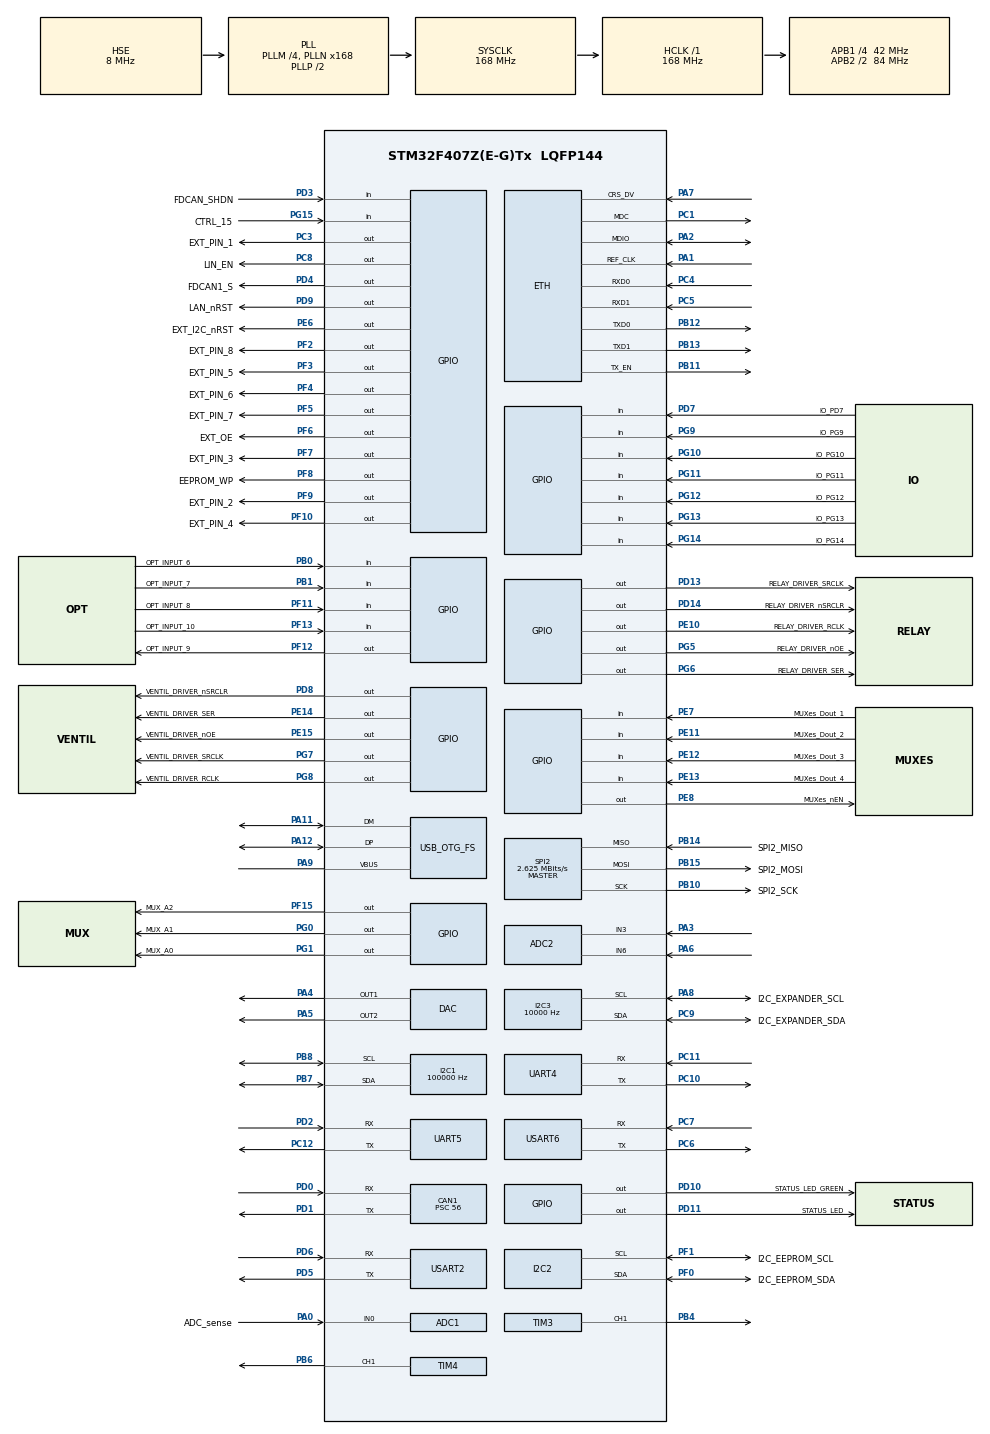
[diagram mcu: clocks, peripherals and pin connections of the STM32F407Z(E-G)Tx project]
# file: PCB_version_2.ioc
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ADC1.Channel-1\#ChannelRegularConversion=ADC_CHANNEL_TEMPSENSOR
ADC1.ContinuousConvMode=ENABLE
ADC1.EOCSelection=ADC_EOC_SEQ_CONV
ADC1.NbrOfConversion=1
ADC1.NbrOfConversionFlag=1
ADC1.SamplingTime-1\#ChannelRegularConversion=ADC_SAMPLETIME_480CYCLES
ADC1.master=1
ADC2.Channel-3\#ChannelRegularConversion=ADC_CHANNEL_3
ADC2.ContinuousConvMode=DISABLE
ADC2.InjNumberOfConversion=0
ADC2.NbrOfConversion=1
ADC2.NbrOfConversionFlag=1
ADC2.Rank-3\#ChannelRegularConversion=1
ADC2.SamplingTime-3\#ChannelRegularConversion=ADC_SAMPLETIME_480CYCLES
ADC2.ScanConvMode=DISABLE
CAN1.CalculateBaudRate=249999
CAN1.CalculateTimeBit=4000
CAN1.CalculateTimeQuantum=1333.3333333333335
CAN1.Mode=CAN_MODE_LOOPBACK
CAN1.Prescaler=56
Dma.Request0=UART4_RX
Dma.Request1=UART5_RX
Dma.UART4_RX.0.Direction=DMA_PERIPH_TO_MEMORY
Dma.UART4_RX.0.FIFOMode=DMA_FIFOMODE_DISABLE
Dma.UART4_RX.0.Instance=DMA1_Stream2
Dma.UART4_RX.0.MemDataAlignment=DMA_MDATAALIGN_BYTE
Dma.UART4_RX.0.MemInc=DMA_MINC_ENABLE
Dma.UART4_RX.0.Mode=DMA_CIRCULAR
Dma.UART4_RX.0.PeriphDataAlignment=DMA_PDATAALIGN_BYTE
Dma.UART4_RX.0.PeriphInc=DMA_PINC_DISABLE
Dma.UART4_RX.0.Priority=DMA_PRIORITY_MEDIUM
Dma.UART5_RX.1.Direction=DMA_PERIPH_TO_MEMORY
Dma.UART5_RX.1.FIFOMode=DMA_FIFOMODE_DISABLE
Dma.UART5_RX.1.Instance=DMA1_Stream0
Dma.UART5_RX.1.MemDataAlignment=DMA_MDATAALIGN_BYTE
Dma.UART5_RX.1.MemInc=DMA_MINC_ENABLE
Dma.UART5_RX.1.Mode=DMA_CIRCULAR
Dma.UART5_RX.1.PeriphDataAlignment=DMA_PDATAALIGN_BYTE
Dma.UART5_RX.1.PeriphInc=DMA_PINC_DISABLE
Dma.UART5_RX.1.Priority=DMA_PRIORITY_MEDIUM
ETH.MACAddr=00\:80\:E1\:01\:23\:45
ETH.MediaInterface=HAL_ETH_RMII_MODE
FREERTOS.BinarySemaphores01=InitDoneSemaphore,Static,InitDoneSemaphoreControlBlock,Available
FREERTOS.INCLUDE_eTaskGetState=1
FREERTOS.INCLUDE_pcTaskGetTaskName=1
FREERTOS.INCLUDE_uxTaskGetStackHighWaterMark=1
FREERTOS.INCLUDE_uxTaskGetStackHighWaterMark2=1
FREERTOS.INCLUDE_vTaskCleanUpResources=1
FREERTOS.INCLUDE_vTaskDelayUntil=1
FREERTOS.INCLUDE_xQueueGetMutexHolder=1
FREERTOS.INCLUDE_xSemaphoreGetMutexHolder=1
FREERTOS.INCLUDE_xTaskAbortDelay=1
FREERTOS.INCLUDE_xTaskGetCurrentTaskHandle=1
FREERTOS.INCLUDE_xTaskGetHandle=1
FREERTOS.MEMORY_ALLOCATION=2
FREERTOS.Tasks01=defaultTask,0,256,StartDefaultTask,Default,NULL,Static,defaultTaskBuffer,defaultTaskControlBlock;blinkTask,-1,128,blinkTaskEntry,Default,NULL,Static,blinkTaskBuffer,blinkTaskControlBlock;watchdogTask,-1,128,watchDogReset,Default,NULL,Static,watchdogTaskBuffer,watchdogTaskControlBlock;TcpServerTask,0,256,TcpServerTaskStart,Default,NULL,Static,TcpServerTaskBuffer,TcpServerTaskControlBlock;UsbTask,0,256,UsbTaskStart,Default,NULL,Static,UsbTaskBuffer,UsbTaskControlBlock;RS232Task,0,256,RS232TaskStart,Default,NULL,Static,RS232TaskBuffer,RS232TaskControlBlock;CommParserTask,0,2048,CommParserTaskStart,Default,NULL,Static,CommParserTaskBuffer,CommParserTaskControlBlock
FREERTOS.configENABLE_FPU=1
FREERTOS.configMINIMAL_STACK_SIZE=128
FREERTOS.configTOTAL_HEAP_SIZE=10000
FREERTOS.configUSE_NEWLIB_REENTRANT=1
I2C1.ClockSpeed=100000
I2C1.I2C_Mode=I2C_Fast
I2C3.ClockSpeed=10000
I2C3.I2C_Mode=I2C_Fast
I2C3.NoStretchMode=I2C_NOSTRETCH_DISABLE
IWDG.Prescaler=IWDG_PRESCALER_128
IWDG.Reload=2500
LWIP.BSP.number=1
LWIP.CMSIS_VERSION-Enabled=1
LWIP.GATEWAY_ADDRESS=192.168.000.001
LWIP.IP_ADDRESS=192.168.000.035
LWIP.LWIP_DHCP=0
LWIP.NETMASK_ADDRESS=255.255.255.000
LWIP.Version=v2.1.2_Cube
LWIP0.BSP.STBoard=false
LWIP0.BSP.api=BSP_COMPONENT_DRIVER
LWIP0.BSP.component=DP83848
LWIP0.BSP.instance=DP83848
LWIP0.BSP.name=Driver_PHY
LWIP0.BSP.semaphore=S_DP83848
LWIP0.BSP.solution=DP83848
Mcu.Family=STM32F4
Mcu.Name=STM32F407Z(E-G)Tx
Mcu.Package=LQFP144
NVIC.CAN1_RX0_IRQn=true\:5\:0\:false\:false\:true\:true\:true\:true\:true
NVIC.CAN1_RX1_IRQn=true\:5\:0\:false\:false\:true\:true\:true\:true\:true
NVIC.DMA1_Stream0_IRQn=true\:5\:0\:false\:false\:true\:true\:false\:true\:true
NVIC.DMA1_Stream2_IRQn=true\:5\:0\:false\:false\:true\:true\:false\:true\:true
NVIC.ETH_IRQn=true\:5\:0\:false\:false\:true\:true\:true\:true\:true
NVIC.OTG_FS_IRQn=true\:5\:0\:false\:false\:true\:true\:false\:true\:true
NVIC.PriorityGroup=NVIC_PRIORITYGROUP_4
NVIC.TIM1_TRG_COM_TIM11_IRQn=true\:5\:0\:false\:false\:true\:true\:true\:true\:true
NVIC.TIM7_IRQn=true\:5\:0\:false\:false\:true\:true\:true\:true\:true
NVIC.TIM8_TRG_COM_TIM14_IRQn=true\:15\:0\:false\:false\:true\:false\:false\:true\:true
NVIC.TimeBase=TIM8_TRG_COM_TIM14_IRQn
NVIC.TimeBaseIP=TIM14
NVIC.UART4_IRQn=true\:5\:0\:false\:false\:true\:true\:true\:true\:true
NVIC.UART5_IRQn=true\:5\:0\:false\:false\:true\:true\:true\:true\:true
PA0-WKUP.GPIO_Label=ADC_sense
PA0-WKUP.Signal=ADCx_IN0
PA1.Mode=RMII
PA1.Signal=ETH_REF_CLK
PA11.Mode=Device_Only
PA11.Signal=USB_OTG_FS_DM
PA12.Mode=Device_Only
PA12.Signal=USB_OTG_FS_DP
PA13.Mode=Trace_Asynchronous_SW
PA13.Signal=SYS_JTMS-SWDIO
PA14.Mode=Trace_Asynchronous_SW
PA14.Signal=SYS_JTCK-SWCLK
PA2.Mode=RMII
PA2.Signal=ETH_MDIO
PA3.Signal=ADCx_IN3
PA4.Signal=COMP_DAC1_group
PA5.Signal=COMP_DAC2_group
PA6.Signal=ADCx_IN6
PA7.Mode=RMII
PA7.Signal=ETH_CRS_DV
PA8.GPIO_Label=I2C_EXPANDER_SCL
PA8.Mode=I2C
PA8.Signal=I2C3_SCL
PA9.Mode=Activate_VBUS
PA9.Signal=USB_OTG_FS_VBUS
PB0.GPIO_Label=OPT_INPUT_6
PB0.Signal=GPIO_Input
PB1.GPIO_Label=OPT_INPUT_7
PB1.Signal=GPIO_Input
PB10.GPIO_Label=SPI2_SCK
PB10.GPIO_PuPd=GPIO_NOPULL
PB10.Mode=Full_Duplex_Master
PB10.Signal=SPI2_SCK
PB11.Mode=RMII
PB11.Signal=ETH_TX_EN
PB12.Mode=RMII
PB12.Signal=ETH_TXD0
PB13.Mode=RMII
PB13.Signal=ETH_TXD1
PB14.GPIO_Label=SPI2_MISO
PB14.Mode=Full_Duplex_Master
PB14.Signal=SPI2_MISO
PB15.GPIO_Label=SPI2_MOSI
PB15.Mode=Full_Duplex_Master
PB15.Signal=SPI2_MOSI
PB3.Mode=Trace_Asynchronous_SW
PB3.Signal=SYS_JTDO-SWO
PB4.Signal=S_TIM3_CH1
PB6.Signal=S_TIM4_CH1
PB7.Mode=I2C
PB7.Signal=I2C1_SDA
PB8.Mode=I2C
PB8.Signal=I2C1_SCL
PC1.Mode=RMII
PC1.Signal=ETH_MDC
PC10.Mode=Asynchronous
PC10.Signal=UART4_TX
PC11.Mode=Asynchronous
PC11.Signal=UART4_RX
PC12.Mode=Asynchronous
PC12.Signal=UART5_TX
PC3.GPIO_Label=EXT_PIN_1
PC3.Signal=GPIO_Output
PC4.Mode=RMII
PC4.Signal=ETH_RXD0
PC5.Mode=RMII
PC5.Signal=ETH_RXD1
PC6.Mode=LIN
PC6.Signal=USART6_TX
PC7.Mode=LIN
PC7.Signal=USART6_RX
PC8.GPIO_Label=LIN_EN
PC8.Signal=GPIO_Output
PC9.GPIO_Label=I2C_EXPANDER_SDA
PC9.Mode=I2C
PC9.Signal=I2C3_SDA
PD0.GPIO_PuPd=GPIO_NOPULL
PD0.Mode=CAN_Activate
PD0.Signal=CAN1_RX
PD1.GPIO_PuPd=GPIO_NOPULL
PD1.Mode=CAN_Activate
PD1.Signal=CAN1_TX
PD10.GPIO_Label=STATUS_LED_GREEN
PD10.Signal=GPIO_Output
PD11.GPIO_Label=STATUS_LED
PD11.Signal=GPIO_Output
PD13.GPIO_Label=RELAY_DRIVER_SRCLK
PD13.Signal=GPIO_Output
PD14.GPIO_Label=RELAY_DRIVER_nSRCLR
PD14.Signal=GPIO_Output
PD2.Mode=Asynchronous
PD2.Signal=UART5_RX
PD3.GPIO_Label=FDCAN_SHDN
PD3.Signal=GPIO_Input
PD4.GPIO_Label=FDCAN1_S
PD4.Signal=GPIO_Output
PD5.Mode=Asynchronous
PD5.Signal=USART2_TX
PD6.Mode=Asynchronous
PD6.Signal=USART2_RX
PD7.GPIO_Label=IO_PD7
PD7.Signal=GPIO_Input
PD8.GPIO_Label=VENTIL_DRIVER_nSRCLR
PD8.Signal=GPIO_Output
PD9.GPIO_Label=LAN_nRST
PD9.Signal=GPIO_Output
PE10.GPIO_Label=RELAY_DRIVER_RCLK
PE10.Signal=GPIO_Output
PE11.GPIO_Label=MUXes_Dout_2
PE11.Signal=GPIO_Input
PE12.GPIO_Label=MUXes_Dout_3
PE12.Signal=GPIO_Input
PE13.GPIO_Label=MUXes_Dout_4
PE13.Signal=GPIO_Input
PE14.GPIO_Label=VENTIL_DRIVER_SER
PE14.Signal=GPIO_Output
PE15.GPIO_Label=VENTIL_DRIVER_nOE
PE15.Signal=GPIO_Output
PE6.GPIO_Label=EXT_I2C_nRST
PE6.Signal=GPIO_Output
PE7.GPIO_Label=MUXes_Dout_1
PE7.Signal=GPIO_Input
PE8.GPIO_Label=MUXes_nEN
PE8.GPIO_Speed=GPIO_SPEED_FREQ_MEDIUM
PE8.Signal=GPIO_Output
PF0.GPIO_Label=I2C_EEPROM_SDA
PF0.GPIO_Pu=GPIO_PULLUP
PF0.Mode=I2C
PF0.Signal=I2C2_SDA
PF1.GPIO_Label=I2C_EEPROM_SCL
PF1.GPIO_Pu=GPIO_PULLUP
PF1.Mode=I2C
PF1.Signal=I2C2_SCL
PF10.GPIO_Label=EXT_PIN_4
PF10.Signal=GPIO_Output
PF11.GPIO_Label=OPT_INPUT_8
PF11.Signal=GPIO_Input
PF12.GPIO_Label=OPT_INPUT_9
PF12.Signal=GPIO_Output
PF13.GPIO_Label=OPT_INPUT_10
PF13.Signal=GPIO_Input
PF15.GPIO_Label=MUX_A2
PF15.Signal=GPIO_Output
PF2.GPIO_Label=EXT_PIN_8
PF2.Signal=GPIO_Output
PF3.GPIO_Label=EXT_PIN_5
PF3.Signal=GPIO_Output
PF4.GPIO_Label=EXT_PIN_6
PF4.Signal=GPIO_Output
PF5.GPIO_Label=EXT_PIN_7
PF5.Signal=GPIO_Output
PF6.GPIO_Label=EXT_OE
PF6.Signal=GPIO_Output
PF7.GPIO_Label=EXT_PIN_3
PF7.Signal=GPIO_Output
PF8.GPIO_Label=EEPROM_WP
PF8.Signal=GPIO_Output
PF9.GPIO_Label=EXT_PIN_2
PF9.Signal=GPIO_Output
PG0.GPIO_Label=MUX_A1
PG0.Signal=GPIO_Output
PG1.GPIO_Label=MUX_A0
PG1.GPIO_Speed=GPIO_SPEED_FREQ_MEDIUM
PG1.Signal=GPIO_Output
PG10.GPIO_Label=IO_PG10
PG10.Signal=GPIO_Input
PG11.GPIO_Label=IO_PG11
PG11.Signal=GPIO_Input
PG12.GPIO_Label=IO_PG12
PG12.Signal=GPIO_Input
PG13.GPIO_Label=IO_PG13
PG13.Signal=GPIO_Input
PG14.GPIO_Label=IO_PG14
PG14.Signal=GPIO_Input
PG15.GPIO_Label=CTRL_15
PG15.Signal=GPIO_Input
PG5.GPIO_Label=RELAY_DRIVER_nOE
PG5.Signal=GPIO_Output
PG6.GPIO_Label=RELAY_DRIVER_SER
PG6.Signal=GPIO_Output
PG7.GPIO_Label=VENTIL_DRIVER_SRCLK
PG7.Signal=GPIO_Output
PG8.GPIO_Label=VENTIL_DRIVER_RCLK
PG8.Signal=GPIO_Output
PG9.GPIO_Label=IO_PG9
PG9.Signal=GPIO_Input
PH0-OSC_IN.Mode=HSE-External-Oscillator
PH0-OSC_IN.Signal=RCC_OSC_IN
PH1-OSC_OUT.Mode=HSE-External-Oscillator
PH1-OSC_OUT.Signal=RCC_OSC_OUT
ProjectManager.HeapSize=0x200
ProjectManager.StackSize=0x400
ProjectManager.TargetToolchain=CMake
RCC.48MHZClocksFreq_Value=48000000
RCC.AHBFreq_Value=168000000
RCC.APB1CLKDivider=RCC_HCLK_DIV4
RCC.APB1Freq_Value=42000000
RCC.APB1TimFreq_Value=84000000
RCC.APB2CLKDivider=RCC_HCLK_DIV2
RCC.APB2Freq_Value=84000000
RCC.APB2TimFreq_Value=168000000
RCC.CortexFreq_Value=168000000
RCC.HCLKFreq_Value=168000000
RCC.HSE_VALUE=8000000
RCC.HSI_VALUE=16000000
RCC.LSE_VALUE=32768
RCC.PLLM=4
RCC.PLLN=168
RCC.PLLQ=7
RCC.RCC_RTC_Clock_Source=RCC_RTCCLKSOURCE_LSE
RCC.RCC_RTC_Clock_SourceVirtual=RCC_RTCCLKSOURCE_LSE
RCC.RCC_RTC_Clock_Source_FROM_HSE=RCC_RTCCLKSOURCE_HSE_DIV9
RCC.SYSCLKFreq_VALUE=168000000
RCC.SYSCLKSource=RCC_SYSCLKSOURCE_PLLCLK
RCC.VCOOutputFreq_Value=336000000
SH.ADCx_IN0.0=ADC1_IN0,IN0
SH.ADCx_IN3.0=ADC2_IN3,IN3
SH.ADCx_IN6.0=ADC2_IN6,IN6
SH.COMP_DAC1_group.0=DAC_OUT1,DAC_OUT1
SH.COMP_DAC2_group.0=DAC_OUT2,DAC_OUT2
SH.S_TIM3_CH1.0=TIM3_CH1,PWM Generation1 CH1
SH.S_TIM4_CH1.0=TIM4_CH1,PWM Generation1 CH1
SPI2.BaudRatePrescaler=SPI_BAUDRATEPRESCALER_16
SPI2.CLKPhase=SPI_PHASE_2EDGE
SPI2.CLKPolarity=SPI_POLARITY_HIGH
SPI2.CalculateBaudRate=2.625 MBits/s
SPI2.Direction=SPI_DIRECTION_2LINES
SPI2.Mode=SPI_MODE_MASTER
SPI2.VirtualType=VM_MASTER
TIM11.AutoReloadPreload=TIM_AUTORELOAD_PRELOAD_ENABLE
TIM11.Period=420-1
TIM3.Channel-PWM\ Generation1\ CH1=TIM_CHANNEL_1
TIM4.Channel-PWM\ Generation1\ CH1=TIM_CHANNEL_1
TIM7.AutoReloadPreload=TIM_AUTORELOAD_PRELOAD_ENABLE
TIM7.Period=168-1
UART4.VirtualMode=Asynchronous
UART5.VirtualMode=Asynchronous
USART2.VirtualMode=VM_ASYNC
USART6.VirtualMode=VM_ASYNC
USB_DEVICE.CLASS_NAME_FS=CDC
USB_DEVICE.VirtualMode-CDC_FS=Cdc
USB_DEVICE.VirtualModeFS=Cdc_FS
USB_OTG_FS.VirtualMode=Device_Only
VP_ADC1_TempSens_Input.Mode=IN-TempSens
VP_ADC1_Vref_Input.Mode=IN-Vrefint
VP_FREERTOS_VS_CMSIS_V1.Mode=CMSIS_V1
VP_IWDG_VS_IWDG.Mode=IWDG_Activate
VP_LWIP_VS_Enabled.Mode=Enabled
VP_SYS_VS_tim14.Mode=TIM14
VP_TIM11_VS_ClockSourceINT.Mode=Enable_Timer
VP_TIM7_VS_ClockSourceINT.Mode=Enable_Timer
VP_USB_DEVICE_VS_USB_DEVICE_CDC_FS.Mode=CDC_FS
board=custom

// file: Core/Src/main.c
/* USER CODE BEGIN Header */
/**
  ******************************************************************************
  * @file           : main.c
  * @brief          : Main program body
  ******************************************************************************
  * @attention
  *
  * Copyright (c) 2023 STMicroelectronics.
  * All rights reserved.
  *
  * This software is licensed under terms that can be found in the LICENSE file
  * in the root directory of this software component.
  * If no LICENSE file comes with this software, it is provided AS-IS.
  *
  ******************************************************************************
  */
/* USER CODE END Header */
#include "main.h"
#include "cmsis_os.h"
#include "lwip.h"
#include "usb_device.h"

/* USER CODE BEGIN Includes */
#include "usbd_cdc_if.h"
#include "stdio.h"
#include "task.h"
#include "semphr.h"
#include "tcpserver.h"
#include "globals.h"
#include "USBMessageHanler.h"
#include "RELAYS_AND_IO_DRIVER.h"
#include "relayCards.h"
#include "I2C_PCA9548APWR_expander.h"
#include "RAFION_bitbang_I2C.h"

#include "VL53L1X_RAFIONTECH.h"
#include "commandParser.h"
#include "UartMessageHandler.h"
/* USER CODE END Includes */

/* USER CODE BEGIN PM */
HAL_StatusTypeDef status;
uint32_t Reg_Val;
extern RELAY_IO_DRIVER_STRUCT RELAY_IO_DRIVER;
extern ExternalPortMapping EXTERNAL_PORT_MAPPING;
extern ExternalRelayCard EXTERNAL_32_RELAY_CARD;

/* USER CODE END PM */

ADC_HandleTypeDef hadc1;
ADC_HandleTypeDef hadc2;

CAN_HandleTypeDef hcan1;

DAC_HandleTypeDef hdac;

I2C_HandleTypeDef hi2c1;
I2C_HandleTypeDef hi2c2;
I2C_HandleTypeDef hi2c3;

IWDG_HandleTypeDef hiwdg;

SPI_HandleTypeDef hspi2;

TIM_HandleTypeDef htim3;
TIM_HandleTypeDef htim4;
TIM_HandleTypeDef htim7;
TIM_HandleTypeDef htim11;

UART_HandleTypeDef huart4;
UART_HandleTypeDef huart5;
UART_HandleTypeDef huart2;
UART_HandleTypeDef huart6;
DMA_HandleTypeDef hdma_uart4_rx;
DMA_HandleTypeDef hdma_uart5_rx;

osThreadId defaultTaskHandle;
uint32_t defaultTaskBuffer[ 256 ];
osStaticThreadDef_t defaultTaskControlBlock;
osThreadId blinkTaskHandle;
uint32_t blinkTaskBuffer[ 128 ];
osStaticThreadDef_t blinkTaskControlBlock;
osThreadId watchdogTaskHandle;
uint32_t watchdogTaskBuffer[ 128 ];
osStaticThreadDef_t watchdogTaskControlBlock;
osThreadId TcpServerTaskHandle;
uint32_t TcpServerTaskBuffer[ 256 ];
osStaticThreadDef_t TcpServerTaskControlBlock;
osThreadId UsbTaskHandle;
uint32_t UsbTaskBuffer[ 256 ];
osStaticThreadDef_t UsbTaskControlBlock;
osThreadId RS232TaskHandle;
uint32_t RS232TaskBuffer[ 256 ];
osStaticThreadDef_t RS232TaskControlBlock;
osThreadId CommParserTaskHandle;
uint32_t CommParserTaskBuffer[ 2048 ];
osStaticThreadDef_t CommParserTaskControlBlock;
osSemaphoreId InitDoneSemaphoreHandle;
osStaticSemaphoreDef_t InitDoneSemaphoreControlBlock;
/* USER CODE BEGIN PV */
osMutexId take_measurement_mutex;
osMutexId isBusyWithSendingResponse_mutex;

uartHandlerStruct uart4_handler_struct = {
  .huart = &huart4,
  .message_was_received_flag = 0,
  .connected_as_bridge = 0,
  .uart_name = "RS232-1",
  .DMA_BUFFER_SIZE = CMD_UART_BUFFER_LENGTH
};

uartHandlerStruct uart5_handler_struct = {
  .huart = &huart5,
  .message_was_received_flag = 0,
  .connected_as_bridge = 0,
  .uart_name = "RS232-2",
  .DMA_BUFFER_SIZE = CMD_UART_BUFFER_LENGTH
};

PCA9548APWRHandle pca9548apwr_expander = {
    .nrst = EXT_I2C_nRST_Pin,
    .scl = I2C_EXPANDER_SCL_Pin,
    .sda = I2C_EXPANDER_SDA_Pin,
    .nrst_port = EXT_I2C_nRST_GPIO_Port,
    .scl_port = I2C_EXPANDER_SCL_GPIO_Port,
    .sda_port = I2C_EXPANDER_SDA_GPIO_Port,
    .i2c_handle = &hi2c3,
    .address = 0x70, //PCA9548APWR default address with all address pins grounded
    .selected_channel = PCA9548APWR_NO_CHANNEL_SELECTED,
    .clock_speed = 10000, //10kHz I2C speed
    .last_i2c_error = HAL_OK
};

  VL53L1X g_tof_sensor1;
  VL53L1X tof_sensor_instances[8];
  VL53L1X* tof_sensors[8]; //Array to hold up to 8 VL53L1X sensors
/* USER CODE END PV */

void SystemClock_Config(void);
static void MX_GPIO_Init(void);
static void MX_DMA_Init(void);
static void MX_ADC1_Init(void);
static void MX_ADC2_Init(void);
static void MX_DAC_Init(void);
static void MX_CAN1_Init(void);
static void MX_I2C1_Init(void);
static void MX_USART2_UART_Init(void);
static void MX_I2C2_Init(void);
static void MX_TIM11_Init(void);
static void MX_I2C3_Init(void);
static void MX_SPI2_Init(void);
static void MX_IWDG_Init(void);
static void MX_TIM3_Init(void);
static void MX_TIM4_Init(void);
static void MX_UART4_Init(void);
static void MX_UART5_Init(void);
static void MX_USART6_UART_Init(void);
static void MX_TIM7_Init(void);
void StartDefaultTask(void const * argument);
void blinkTaskEntry(void const * argument);
void watchDogReset(void const * argument);
void TcpServerTaskStart(void const * argument);
void UsbTaskStart(void const * argument);
void RS232TaskStart(void const * argument);
void CommParserTaskStart(void const * argument);

/* USER CODE BEGIN PFP */
//Redriect printf to USB CDC
int _write(int file, char *ptr, int len)
{
  CDC_Transmit_FS((uint8_t*)ptr, len);
  return len;
}

/* USER CODE END PFP */

/* USER CODE BEGIN 0 */
volatile const char *g_fault_reason = NULL;
volatile const char *g_fault_task_name = NULL;
volatile uint32_t g_fault_stack_r0 = 0;
volatile uint32_t g_fault_stack_r1 = 0;
volatile uint32_t g_fault_stack_r2 = 0;
volatile uint32_t g_fault_stack_r3 = 0;
volatile uint32_t g_fault_stack_r12 = 0;
volatile uint32_t g_fault_stack_lr = 0;
volatile uint32_t g_fault_stack_pc = 0;
volatile uint32_t g_fault_stack_psr = 0;
volatile uint32_t g_fault_sp = 0;
volatile uint32_t g_fault_exc_return = 0;
volatile uint32_t g_fault_cfsr = 0;
volatile uint32_t g_fault_hfsr = 0;
volatile uint32_t g_fault_dfsr = 0;
volatile uint32_t g_fault_afsr = 0;
volatile uint32_t g_fault_bfar = 0;
volatile uint32_t g_fault_mmfar = 0;

static void DebugTrap(const char *reason, const char *task_name)
{
  g_fault_reason = reason;
  g_fault_task_name = task_name;
  __disable_irq();
  __BKPT(0);
  while (1)
  {
  }
}

static uartHandlerStruct* GetRs232Handler(UART_HandleTypeDef *huart)
{
  // Implement the logic to get the UART handler based on the huart pointer
  // This is a placeholder implementation, replace with actual logic
  if (huart == &huart4)
  {
    return &uart4_handler_struct;
  }
  else if (huart == &huart5)
  {
    return &uart5_handler_struct;
  }
  return NULL;
}

void HAL_UARTEx_RxEventCallback(UART_HandleTypeDef *huart, uint16_t Size)
{
  uartHandlerStruct *uart_handler = GetRs232Handler(huart);
  uint16_t write_position = Size;
  uint16_t previous_position;
  uint16_t received_bytes;

  if (uart_handler == NULL)
  {
    return;
  }

  if (write_position > uart_handler->DMA_BUFFER_SIZE)
  {
    write_position = uart_handler->DMA_BUFFER_SIZE;
  }

  previous_position = uart_handler->dma_write_position;

  if (write_position == uart_handler->DMA_BUFFER_SIZE)
  {
    received_bytes = (uint16_t)(uart_handler->DMA_BUFFER_SIZE - previous_position);
    uart_handler->dma_write_position = 0U;
  }
  else if (write_position >= previous_position)
  {
    received_bytes = (uint16_t)(write_position - previous_position);
    uart_handler->dma_write_position = write_position;
  }
  else
  {
    received_bytes = (uint16_t)(uart_handler->DMA_BUFFER_SIZE - previous_position + write_position);
    uart_handler->dma_write_position = write_position;
  }

  if (received_bytes == 0U)
  {
    return;
  }

  if ((uint16_t)(uart_handler->dma_pending_bytes + received_bytes) > uart_handler->DMA_BUFFER_SIZE)
  {
    uart_handler->dma_pending_bytes = uart_handler->DMA_BUFFER_SIZE;
  }
  else
  {
    uart_handler->dma_pending_bytes = (uint16_t)(uart_handler->dma_pending_bytes + received_bytes);
  }

  uart_handler->message_length = uart_handler->dma_pending_bytes;
  uart_handler->message_was_received_flag = 1U;
}

/* USER CODE END 0 */

int main(void)
{

  /* MCU Configuration--------------------------------------------------------*/

  /* Reset of all peripherals, Initializes the Flash interface and the Systick. */
  HAL_Init();

  /* USER CODE BEGIN Init */
  //SCB->VTOR = 0x08020000; // Set vector table base address
  //eenable interrupts
  __enable_irq();

  SCB->SHCSR |= SCB_SHCSR_MEMFAULTENA_Msk |
                SCB_SHCSR_BUSFAULTENA_Msk |
                SCB_SHCSR_USGFAULTENA_Msk;
  SCB->CCR |= SCB_CCR_DIV_0_TRP_Msk;

  /* USER CODE END Init */

  /* Configure the system clock */
  SystemClock_Config();

  /* Initialize all configured peripherals */
  MX_GPIO_Init();
  MX_DMA_Init();
  MX_ADC1_Init();
  MX_ADC2_Init();
  MX_DAC_Init();
  MX_CAN1_Init();
  MX_I2C1_Init();
  MX_USART2_UART_Init();
  MX_I2C2_Init();
  MX_TIM11_Init();
  MX_I2C3_Init();
  MX_SPI2_Init();
  MX_IWDG_Init();
  MX_TIM3_Init();
  MX_TIM4_Init();
  MX_UART4_Init();
  MX_UART5_Init();
  MX_USART6_UART_Init();
  MX_TIM7_Init();
  /* USER CODE BEGIN 2 */
  HAL_GPIO_WritePin(STATUS_LED_GREEN_GPIO_Port,STATUS_LED_GREEN_Pin, GPIO_PIN_SET);
  HAL_ADC_Start(&hadc1);
  HAL_ADC_Start(&hadc2);
  HAL_TIM_Base_Start_IT(&htim11);
  HAL_TIM_Base_Start_IT(&htim7);

  RELAY_DRIVER_init(&RELAY_IO_DRIVER);
  HAL_GPIO_WritePin(EXTERNAL_PORT_MAPPING.EXT_OE_port, EXTERNAL_PORT_MAPPING.EXT_OE_pin, GPIO_PIN_SET);
  relayCardSetPort(0,&EXTERNAL_32_RELAY_CARD);
  HAL_GPIO_WritePin(LAN_nRST_GPIO_Port,LAN_nRST_Pin, GPIO_PIN_SET);
  HAL_Delay(100);

  /* USER CODE END 2 */

  /* USER CODE BEGIN RTOS_MUTEX */
  /* add mutexes, ... */
  commandTemplateMutex = xSemaphoreCreateMutex();
  if (commandTemplateMutex == NULL)
  {
    Error_Handler();
  }

  /* USER CODE END RTOS_MUTEX */

  /* Create the semaphores(s) */
  /* definition and creation of InitDoneSemaphore */
  osSemaphoreStaticDef(InitDoneSemaphore, &InitDoneSemaphoreControlBlock);
  InitDoneSemaphoreHandle = osSemaphoreCreate(osSemaphore(InitDoneSemaphore), 1);

  /* USER CODE BEGIN RTOS_SEMAPHORES */
  osMutexDef(take_measurement_mutex);
  take_measurement_mutex = osMutexCreate(osMutex(take_measurement_mutex));

  osMutexDef(isBusyWithSendingResponse_mutex);
  isBusyWithSendingResponse_mutex = osMutexCreate(osMutex(isBusyWithSendingResponse_mutex));
  /* add semaphores, ... */
  /* USER CODE END RTOS_SEMAPHORES */

  /* USER CODE BEGIN RTOS_QUEUES */
  /* add queues, ... */
  init_command_queue();
  if (commandQueueHandle == NULL)
  {
    Error_Handler();
  }
  /* USER CODE END RTOS_QUEUES */

  /* Create the thread(s) */
  /* definition and creation of defaultTask */
  osThreadStaticDef(defaultTask, StartDefaultTask, osPriorityNormal, 0, 256, defaultTaskBuffer, &defaultTaskControlBlock);
  defaultTaskHandle = osThreadCreate(osThread(defaultTask), NULL);

  /* definition and creation of blinkTask */
  osThreadStaticDef(blinkTask, blinkTaskEntry, osPriorityBelowNormal, 0, 128, blinkTaskBuffer, &blinkTaskControlBlock);
  blinkTaskHandle = osThreadCreate(osThread(blinkTask), NULL);

  /* definition and creation of watchdogTask */
  osThreadStaticDef(watchdogTask, watchDogReset, osPriorityBelowNormal, 0, 128, watchdogTaskBuffer, &watchdogTaskControlBlock);
  watchdogTaskHandle = osThreadCreate(osThread(watchdogTask), NULL);

  /* definition and creation of TcpServerTask */
  osThreadStaticDef(TcpServerTask, TcpServerTaskStart, osPriorityNormal, 0, 256, TcpServerTaskBuffer, &TcpServerTaskControlBlock);
  TcpServerTaskHandle = osThreadCreate(osThread(TcpServerTask), NULL);

  /* definition and creation of UsbTask */
  osThreadStaticDef(UsbTask, UsbTaskStart, osPriorityNormal, 0, 256, UsbTaskBuffer, &UsbTaskControlBlock);
  UsbTaskHandle = osThreadCreate(osThread(UsbTask), NULL);

  /* definition and creation of RS232Task */
  osThreadStaticDef(RS232Task, RS232TaskStart, osPriorityNormal, 0, 256, RS232TaskBuffer, &RS232TaskControlBlock);
  RS232TaskHandle = osThreadCreate(osThread(RS232Task), NULL);

  /* definition and creation of CommParserTask */
  osThreadStaticDef(CommParserTask, CommParserTaskStart, osPriorityNormal, 0, 2048, CommParserTaskBuffer, &CommParserTaskControlBlock);
  CommParserTaskHandle = osThreadCreate(osThread(CommParserTask), NULL);

  /* USER CODE BEGIN RTOS_THREADS */
  if ((defaultTaskHandle == NULL) ||
      (blinkTaskHandle == NULL) ||
      (watchdogTaskHandle == NULL) ||
      (TcpServerTaskHandle == NULL) ||
      (UsbTaskHandle == NULL) ||
      (RS232TaskHandle == NULL) ||
      (CommParserTaskHandle == NULL))
  {
    Error_Handler();
  }
  /* USER CODE END RTOS_THREADS */

  /* Start scheduler */
  osKernelStart();

  /* We should never get here as control is now taken by the scheduler */

  /* Infinite loop */
  while (1)
  {

  }
}

void SystemClock_Config(void)
{
  RCC_OscInitTypeDef RCC_OscInitStruct = {0};
  RCC_ClkInitTypeDef RCC_ClkInitStruct = {0};

  /** Configure the main internal regulator output voltage
  */
  __HAL_RCC_PWR_CLK_ENABLE();
  __HAL_PWR_VOLTAGESCALING_CONFIG(PWR_REGULATOR_VOLTAGE_SCALE1);

  /** Initializes the RCC Oscillators according to the specified parameters
  * in the RCC_OscInitTypeDef structure.
  */
  RCC_OscInitStruct.OscillatorType = RCC_OSCILLATORTYPE_LSI|RCC_OSCILLATORTYPE_HSE;
  RCC_OscInitStruct.HSEState = RCC_HSE_ON;
  RCC_OscInitStruct.LSIState = RCC_LSI_ON;
  RCC_OscInitStruct.PLL.PLLState = RCC_PLL_ON;
  RCC_OscInitStruct.PLL.PLLSource = RCC_PLLSOURCE_HSE;
  RCC_OscInitStruct.PLL.PLLM = 4;
  RCC_OscInitStruct.PLL.PLLN = 168;
  RCC_OscInitStruct.PLL.PLLP = RCC_PLLP_DIV2;
  RCC_OscInitStruct.PLL.PLLQ = 7;
  if (HAL_RCC_OscConfig(&RCC_OscInitStruct) != HAL_OK)
  {
    Error_Handler();
  }

  /** Initializes the CPU, AHB and APB buses clocks
  */
  RCC_ClkInitStruct.ClockType = RCC_CLOCKTYPE_HCLK|RCC_CLOCKTYPE_SYSCLK
                              |RCC_CLOCKTYPE_PCLK1|RCC_CLOCKTYPE_PCLK2;
  RCC_ClkInitStruct.SYSCLKSource = RCC_SYSCLKSOURCE_PLLCLK;
  RCC_ClkInitStruct.AHBCLKDivider = RCC_SYSCLK_DIV1;
  RCC_ClkInitStruct.APB1CLKDivider = RCC_HCLK_DIV4;
  RCC_ClkInitStruct.APB2CLKDivider = RCC_HCLK_DIV2;

  if (HAL_RCC_ClockConfig(&RCC_ClkInitStruct, FLASH_LATENCY_5) != HAL_OK)
  {
    Error_Handler();
  }
}

static void MX_ADC1_Init(void)
{

  ADC_ChannelConfTypeDef sConfig = {0};

  /** Configure the global features of the ADC (Clock, Resolution, Data Alignment and number of conversion)
  */
  hadc1.Instance = ADC1;
  hadc1.Init.ClockPrescaler = ADC_CLOCK_SYNC_PCLK_DIV4;
  hadc1.Init.Resolution = ADC_RESOLUTION_12B;
  hadc1.Init.ScanConvMode = DISABLE;
  hadc1.Init.ContinuousConvMode = ENABLE;
  hadc1.Init.DiscontinuousConvMode = DISABLE;
  hadc1.Init.ExternalTrigConvEdge = ADC_EXTERNALTRIGCONVEDGE_NONE;
  hadc1.Init.ExternalTrigConv = ADC_SOFTWARE_START;
  hadc1.Init.DataAlign = ADC_DATAALIGN_RIGHT;
  hadc1.Init.NbrOfConversion = 1;
  hadc1.Init.DMAContinuousRequests = DISABLE;
  hadc1.Init.EOCSelection = ADC_EOC_SEQ_CONV;
  if (HAL_ADC_Init(&hadc1) != HAL_OK)
  {
    Error_Handler();
  }

  /** Configure for the selected ADC regular channel its corresponding rank in the sequencer and its sample time.
  */
  sConfig.Channel = ADC_CHANNEL_TEMPSENSOR;
  sConfig.Rank = 1;
  sConfig.SamplingTime = ADC_SAMPLETIME_480CYCLES;
  if (HAL_ADC_ConfigChannel(&hadc1, &sConfig) != HAL_OK)
  {
    Error_Handler();
  }

}

static void MX_ADC2_Init(void)
{

  ADC_ChannelConfTypeDef sConfig = {0};

  /** Configure the global features of the ADC (Clock, Resolution, Data Alignment and number of conversion)
  */
  hadc2.Instance = ADC2;
  hadc2.Init.ClockPrescaler = ADC_CLOCK_SYNC_PCLK_DIV4;
  hadc2.Init.Resolution = ADC_RESOLUTION_12B;
  hadc2.Init.ScanConvMode = DISABLE;
  hadc2.Init.ContinuousConvMode = DISABLE;
  hadc2.Init.DiscontinuousConvMode = DISABLE;
  hadc2.Init.ExternalTrigConvEdge = ADC_EXTERNALTRIGCONVEDGE_NONE;
  hadc2.Init.ExternalTrigConv = ADC_SOFTWARE_START;
  hadc2.Init.DataAlign = ADC_DATAALIGN_RIGHT;
  hadc2.Init.NbrOfConversion = 1;
  hadc2.Init.DMAContinuousRequests = DISABLE;
  hadc2.Init.EOCSelection = ADC_EOC_SINGLE_CONV;
  if (HAL_ADC_Init(&hadc2) != HAL_OK)
  {
    Error_Handler();
  }

  /** Configure for the selected ADC regular channel its corresponding rank in the sequencer and its sample time.
  */
  sConfig.Channel = ADC_CHANNEL_3;
  sConfig.Rank = 1;
  sConfig.SamplingTime = ADC_SAMPLETIME_480CYCLES;
  if (HAL_ADC_ConfigChannel(&hadc2, &sConfig) != HAL_OK)
  {
    Error_Handler();
  }

}

static void MX_CAN1_Init(void)
{

  hcan1.Instance = CAN1;
  hcan1.Init.Prescaler = 56;
  hcan1.Init.Mode = CAN_MODE_LOOPBACK;
  hcan1.Init.SyncJumpWidth = CAN_SJW_1TQ;
  hcan1.Init.TimeSeg1 = CAN_BS1_1TQ;
  hcan1.Init.TimeSeg2 = CAN_BS2_1TQ;
  hcan1.Init.TimeTriggeredMode = DISABLE;
  hcan1.Init.AutoBusOff = DISABLE;
  hcan1.Init.AutoWakeUp = DISABLE;
  hcan1.Init.AutoRetransmission = DISABLE;
  hcan1.Init.ReceiveFifoLocked = DISABLE;
  hcan1.Init.TransmitFifoPriority = DISABLE;
  if (HAL_CAN_Init(&hcan1) != HAL_OK)
  {
    Error_Handler();
  }

}

static void MX_DAC_Init(void)
{

  DAC_ChannelConfTypeDef sConfig = {0};

  /** DAC Initialization
  */
  hdac.Instance = DAC;
  if (HAL_DAC_Init(&hdac) != HAL_OK)
  {
    Error_Handler();
  }

  /** DAC channel OUT1 config
  */
  sConfig.DAC_Trigger = DAC_TRIGGER_NONE;
  sConfig.DAC_OutputBuffer = DAC_OUTPUTBUFFER_ENABLE;
  if (HAL_DAC_ConfigChannel(&hdac, &sConfig, DAC_CHANNEL_1) != HAL_OK)
  {
    Error_Handler();
  }

  /** DAC channel OUT2 config
  */
  if (HAL_DAC_ConfigChannel(&hdac, &sConfig, DAC_CHANNEL_2) != HAL_OK)
  {
    Error_Handler();
  }
  /* USER CODE BEGIN DAC_Init 2 */
  HAL_DAC_Start(&hdac, DAC_CHANNEL_1);
  /* USER CODE END DAC_Init 2 */

}

static void MX_I2C1_Init(void)
{

  hi2c1.Instance = I2C1;
  hi2c1.Init.ClockSpeed = 100000;
  hi2c1.Init.DutyCycle = I2C_DUTYCYCLE_2;
  hi2c1.Init.OwnAddress1 = 0;
  hi2c1.Init.AddressingMode = I2C_ADDRESSINGMODE_7BIT;
  hi2c1.Init.DualAddressMode = I2C_DUALADDRESS_DISABLE;
  hi2c1.Init.OwnAddress2 = 0;
  hi2c1.Init.GeneralCallMode = I2C_GENERALCALL_DISABLE;
  hi2c1.Init.NoStretchMode = I2C_NOSTRETCH_DISABLE;
  if (HAL_I2C_Init(&hi2c1) != HAL_OK)
  {
    Error_Handler();
  }

}

static void MX_I2C2_Init(void)
{

  hi2c2.Instance = I2C2;
  hi2c2.Init.ClockSpeed = 100000;
  hi2c2.Init.DutyCycle = I2C_DUTYCYCLE_2;
  hi2c2.Init.OwnAddress1 = 0;
  hi2c2.Init.AddressingMode = I2C_ADDRESSINGMODE_7BIT;
  hi2c2.Init.DualAddressMode = I2C_DUALADDRESS_DISABLE;
  hi2c2.Init.OwnAddress2 = 0;
  hi2c2.Init.GeneralCallMode = I2C_GENERALCALL_DISABLE;
  hi2c2.Init.NoStretchMode = I2C_NOSTRETCH_DISABLE;
  if (HAL_I2C_Init(&hi2c2) != HAL_OK)
  {
    Error_Handler();
  }

}

static void MX_I2C3_Init(void)
{

  hi2c3.Instance = I2C3;
  hi2c3.Init.ClockSpeed = 10000;
  hi2c3.Init.DutyCycle = I2C_DUTYCYCLE_2;
  hi2c3.Init.OwnAddress1 = 0;
  hi2c3.Init.AddressingMode = I2C_ADDRESSINGMODE_7BIT;
  hi2c3.Init.DualAddressMode = I2C_DUALADDRESS_DISABLE;
  hi2c3.Init.OwnAddress2 = 0;
  hi2c3.Init.GeneralCallMode = I2C_GENERALCALL_DISABLE;
  hi2c3.Init.NoStretchMode = I2C_NOSTRETCH_DISABLE;
  if (HAL_I2C_Init(&hi2c3) != HAL_OK)
  {
    Error_Handler();
  }

}

static void MX_IWDG_Init(void)
{

  hiwdg.Instance = IWDG;
  hiwdg.Init.Prescaler = IWDG_PRESCALER_128;
  hiwdg.Init.Reload = 2500;
  if (HAL_IWDG_Init(&hiwdg) != HAL_OK)
  {
    Error_Handler();
  }

}

static void MX_SPI2_Init(void)
{

  /* SPI2 parameter configuration*/
  hspi2.Instance = SPI2;
  hspi2.Init.Mode = SPI_MODE_MASTER;
  hspi2.Init.Direction = SPI_DIRECTION_2LINES;
  hspi2.Init.DataSize = SPI_DATASIZE_8BIT;
  hspi2.Init.CLKPolarity = SPI_POLARITY_HIGH;
  hspi2.Init.CLKPhase = SPI_PHASE_2EDGE;
  hspi2.Init.NSS = SPI_NSS_SOFT;
  hspi2.Init.BaudRatePrescaler = SPI_BAUDRATEPRESCALER_16;
  hspi2.Init.FirstBit = SPI_FIRSTBIT_MSB;
  hspi2.Init.TIMode = SPI_TIMODE_DISABLE;
  hspi2.Init.CRCCalculation = SPI_CRCCALCULATION_DISABLE;
  hspi2.Init.CRCPolynomial = 10;
  if (HAL_SPI_Init(&hspi2) != HAL_OK)
  {
    Error_Handler();
  }

}

static void MX_TIM3_Init(void)
{

  TIM_MasterConfigTypeDef sMasterConfig = {0};
  TIM_OC_InitTypeDef sConfigOC = {0};

  htim3.Instance = TIM3;
  htim3.Init.Prescaler = 0;
  htim3.Init.CounterMode = TIM_COUNTERMODE_UP;
  htim3.Init.Period = 65535;
  htim3.Init.ClockDivision = TIM_CLOCKDIVISION_DIV1;
  htim3.Init.AutoReloadPreload = TIM_AUTORELOAD_PRELOAD_DISABLE;
  if (HAL_TIM_PWM_Init(&htim3) != HAL_OK)
  {
    Error_Handler();
  }
  sMasterConfig.MasterOutputTrigger = TIM_TRGO_RESET;
  sMasterConfig.MasterSlaveMode = TIM_MASTERSLAVEMODE_DISABLE;
  if (HAL_TIMEx_MasterConfigSynchronization(&htim3, &sMasterConfig) != HAL_OK)
  {
    Error_Handler();
  }
  sConfigOC.OCMode = TIM_OCMODE_PWM1;
  sConfigOC.Pulse = 0;
  sConfigOC.OCPolarity = TIM_OCPOLARITY_HIGH;
  sConfigOC.OCFastMode = TIM_OCFAST_DISABLE;
  if (HAL_TIM_PWM_ConfigChannel(&htim3, &sConfigOC, TIM_CHANNEL_1) != HAL_OK)
  {
    Error_Handler();
  }
  HAL_TIM_MspPostInit(&htim3);

}

static void MX_TIM4_Init(void)
{

  TIM_MasterConfigTypeDef sMasterConfig = {0};
  TIM_OC_InitTypeDef sConfigOC = {0};

  htim4.Instance = TIM4;
  htim4.Init.Prescaler = 0;
  htim4.Init.CounterMode = TIM_COUNTERMODE_UP;
  htim4.Init.Period = 65535;
  htim4.Init.ClockDivision = TIM_CLOCKDIVISION_DIV1;
  htim4.Init.AutoReloadPreload = TIM_AUTORELOAD_PRELOAD_DISABLE;
  if (HAL_TIM_PWM_Init(&htim4) != HAL_OK)
  {
    Error_Handler();
  }
  sMasterConfig.MasterOutputTrigger = TIM_TRGO_RESET;
  sMasterConfig.MasterSlaveMode = TIM_MASTERSLAVEMODE_DISABLE;
  if (HAL_TIMEx_MasterConfigSynchronization(&htim4, &sMasterConfig) != HAL_OK)
  {
    Error_Handler();
  }
  sConfigOC.OCMode = TIM_OCMODE_PWM1;
  sConfigOC.Pulse = 0;
  sConfigOC.OCPolarity = TIM_OCPOLARITY_HIGH;
  sConfigOC.OCFastMode = TIM_OCFAST_DISABLE;
  if (HAL_TIM_PWM_ConfigChannel(&htim4, &sConfigOC, TIM_CHANNEL_1) != HAL_OK)
  {
    Error_Handler();
  }
  HAL_TIM_MspPostInit(&htim4);

}

static void MX_TIM7_Init(void)
{

  TIM_MasterConfigTypeDef sMasterConfig = {0};

  htim7.Instance = TIM7;
  htim7.Init.Prescaler = 0;
  htim7.Init.CounterMode = TIM_COUNTERMODE_UP;
  htim7.Init.Period = 168-1;
  htim7.Init.AutoReloadPreload = TIM_AUTORELOAD_PRELOAD_ENABLE;
  if (HAL_TIM_Base_Init(&htim7) != HAL_OK)
  {
    Error_Handler();
  }
  sMasterConfig.MasterOutputTrigger = TIM_TRGO_RESET;
  sMasterConfig.MasterSlaveMode = TIM_MASTERSLAVEMODE_DISABLE;
  if (HAL_TIMEx_MasterConfigSynchronization(&htim7, &sMasterConfig) != HAL_OK)
  {
    Error_Handler();
  }

}

static void MX_TIM11_Init(void)
{

  htim11.Instance = TIM11;
  htim11.Init.Prescaler = 0;
  htim11.Init.CounterMode = TIM_COUNTERMODE_UP;
  htim11.Init.Period = 420-1;
  htim11.Init.ClockDivision = TIM_CLOCKDIVISION_DIV1;
  htim11.Init.AutoReloadPreload = TIM_AUTORELOAD_PRELOAD_ENABLE;
  if (HAL_TIM_Base_Init(&htim11) != HAL_OK)
  {
    Error_Handler();
  }

}

static void MX_UART4_Init(void)
{

  huart4.Instance = UART4;
  huart4.Init.BaudRate = 115200;
  huart4.Init.WordLength = UART_WORDLENGTH_8B;
  huart4.Init.StopBits = UART_STOPBITS_1;
  huart4.Init.Parity = UART_PARITY_NONE;
  huart4.Init.Mode = UART_MODE_TX_RX;
  huart4.Init.HwFlowCtl = UART_HWCONTROL_NONE;
  huart4.Init.OverSampling = UART_OVERSAMPLING_16;
  if (HAL_UART_Init(&huart4) != HAL_OK)
  {
    Error_Handler();
  }

}

static void MX_UART5_Init(void)
{

  huart5.Instance = UART5;
  huart5.Init.BaudRate = 115200;
  huart5.Init.WordLength = UART_WORDLENGTH_8B;
  huart5.Init.StopBits = UART_STOPBITS_1;
  huart5.Init.Parity = UART_PARITY_NONE;
  huart5.Init.Mode = UART_MODE_TX_RX;
  huart5.Init.HwFlowCtl = UART_HWCONTROL_NONE;
  huart5.Init.OverSampling = UART_OVERSAMPLING_16;
  if (HAL_UART_Init(&huart5) != HAL_OK)
  {
    Error_Handler();
  }

}

static void MX_USART2_UART_Init(void)
{

  huart2.Instance = USART2;
  huart2.Init.BaudRate = 115200;
  huart2.Init.WordLength = UART_WORDLENGTH_8B;
  huart2.Init.StopBits = UART_STOPBITS_1;
  huart2.Init.Parity = UART_PARITY_NONE;
  huart2.Init.Mode = UART_MODE_TX_RX;
  huart2.Init.HwFlowCtl = UART_HWCONTROL_NONE;
  huart2.Init.OverSampling = UART_OVERSAMPLING_16;
  if (HAL_UART_Init(&huart2) != HAL_OK)
  {
    Error_Handler();
  }

}

static void MX_USART6_UART_Init(void)
{

  huart6.Instance = USART6;
  huart6.Init.BaudRate = 115200;
  huart6.Init.WordLength = UART_WORDLENGTH_8B;
  huart6.Init.StopBits = UART_STOPBITS_1;
  huart6.Init.Parity = UART_PARITY_NONE;
  huart6.Init.Mode = UART_MODE_TX_RX;
  huart6.Init.HwFlowCtl = UART_HWCONTROL_NONE;
  huart6.Init.OverSampling = UART_OVERSAMPLING_16;
  if (HAL_LIN_Init(&huart6, UART_LINBREAKDETECTLENGTH_10B) != HAL_OK)
  {
    Error_Handler();
  }

}

static void MX_DMA_Init(void)
{

  /* DMA controller clock enable */
  __HAL_RCC_DMA1_CLK_ENABLE();

  /* DMA interrupt init */
  /* DMA1_Stream0_IRQn interrupt configuration */
  HAL_NVIC_SetPriority(DMA1_Stream0_IRQn, 5, 0);
  HAL_NVIC_EnableIRQ(DMA1_Stream0_IRQn);
  /* DMA1_Stream2_IRQn interrupt configuration */
  HAL_NVIC_SetPriority(DMA1_Stream2_IRQn, 5, 0);
  HAL_NVIC_EnableIRQ(DMA1_Stream2_IRQn);

}

static void MX_GPIO_Init(void)
{
  GPIO_InitTypeDef GPIO_InitStruct = {0};

  /* GPIO Ports Clock Enable */
  __HAL_RCC_GPIOE_CLK_ENABLE();
  __HAL_RCC_GPIOF_CLK_ENABLE();
  __HAL_RCC_GPIOH_CLK_ENABLE();
  __HAL_RCC_GPIOC_CLK_ENABLE();
  __HAL_RCC_GPIOA_CLK_ENABLE();
  __HAL_RCC_GPIOB_CLK_ENABLE();
  __HAL_RCC_GPIOG_CLK_ENABLE();
  __HAL_RCC_GPIOD_CLK_ENABLE();

  /*Configure GPIO pin Output Level */
  HAL_GPIO_WritePin(GPIOE, EXT_I2C_nRST_Pin|MUXes_nEN_Pin|RELAY_DRIVER_RCLK_Pin|VENTIL_DRIVER_SER_Pin
                          |VENTIL_DRIVER_nOE_Pin, GPIO_PIN_RESET);

  /*Configure GPIO pin Output Level */
  HAL_GPIO_WritePin(GPIOF, EXT_PIN_8_Pin|EXT_PIN_5_Pin|EXT_PIN_6_Pin|EXT_PIN_7_Pin
                          |EXT_OE_Pin|EXT_PIN_3_Pin|EEPROM_WP_Pin|EXT_PIN_2_Pin
                          |EXT_PIN_4_Pin|OPT_INPUT_9_Pin|MUX_A2_Pin, GPIO_PIN_RESET);

  /*Configure GPIO pin Output Level */
  HAL_GPIO_WritePin(GPIOC, EXT_PIN_1_Pin|LIN_EN_Pin, GPIO_PIN_RESET);

  /*Configure GPIO pin Output Level */
  HAL_GPIO_WritePin(GPIOG, MUX_A1_Pin|MUX_A0_Pin|RELAY_DRIVER_nOE_Pin|RELAY_DRIVER_SER_Pin
                          |VENTIL_DRIVER_SRCLK_Pin|VENTIL_DRIVER_RCLK_Pin, GPIO_PIN_RESET);

  /*Configure GPIO pin Output Level */
  HAL_GPIO_WritePin(GPIOD, VENTIL_DRIVER_nSRCLR_Pin|LAN_nRST_Pin|STATUS_LED_GREEN_Pin|STATUS_LED_Pin
                          |RELAY_DRIVER_SRCLK_Pin|RELAY_DRIVER_nSRCLR_Pin|FDCAN1_S_Pin, GPIO_PIN_RESET);

  /*Configure GPIO pins : EXT_I2C_nRST_Pin RELAY_DRIVER_RCLK_Pin VENTIL_DRIVER_SER_Pin VENTIL_DRIVER_nOE_Pin */
  GPIO_InitStruct.Pin = EXT_I2C_nRST_Pin|RELAY_DRIVER_RCLK_Pin|VENTIL_DRIVER_SER_Pin|VENTIL_DRIVER_nOE_Pin;
  GPIO_InitStruct.Mode = GPIO_MODE_OUTPUT_PP;
  GPIO_InitStruct.Pull = GPIO_NOPULL;
  GPIO_InitStruct.Speed = GPIO_SPEED_FREQ_LOW;
  HAL_GPIO_Init(GPIOE, &GPIO_InitStruct);

  /*Configure GPIO pins : EXT_PIN_8_Pin EXT_PIN_5_Pin EXT_PIN_6_Pin EXT_PIN_7_Pin
                           EXT_OE_Pin EXT_PIN_3_Pin EEPROM_WP_Pin EXT_PIN_2_Pin
                           EXT_PIN_4_Pin OPT_INPUT_9_Pin MUX_A2_Pin */
  GPIO_InitStruct.Pin = EXT_PIN_8_Pin|EXT_PIN_5_Pin|EXT_PIN_6_Pin|EXT_PIN_7_Pin
                          |EXT_OE_Pin|EXT_PIN_3_Pin|EEPROM_WP_Pin|EXT_PIN_2_Pin
                          |EXT_PIN_4_Pin|OPT_INPUT_9_Pin|MUX_A2_Pin;
  GPIO_InitStruct.Mode = GPIO_MODE_OUTPUT_PP;
  GPIO_InitStruct.Pull = GPIO_NOPULL;
  GPIO_InitStruct.Speed = GPIO_SPEED_FREQ_LOW;
  HAL_GPIO_Init(GPIOF, &GPIO_InitStruct);

  /*Configure GPIO pins : EXT_PIN_1_Pin LIN_EN_Pin */
  GPIO_InitStruct.Pin = EXT_PIN_1_Pin|LIN_EN_Pin;
  GPIO_InitStruct.Mode = GPIO_MODE_OUTPUT_PP;
  GPIO_InitStruct.Pull = GPIO_NOPULL;
  GPIO_InitStruct.Speed = GPIO_SPEED_FREQ_LOW;
  HAL_GPIO_Init(GPIOC, &GPIO_InitStruct);

  /*Configure GPIO pins : OPT_INPUT_6_Pin OPT_INPUT_7_Pin */
  GPIO_InitStruct.Pin = OPT_INPUT_6_Pin|OPT_INPUT_7_Pin;
  GPIO_InitStruct.Mode = GPIO_MODE_INPUT;
  GPIO_InitStruct.Pull = GPIO_NOPULL;
  HAL_GPIO_Init(GPIOB, &GPIO_InitStruct);

  /*Configure GPIO pins : OPT_INPUT_8_Pin OPT_INPUT_10_Pin */
  GPIO_InitStruct.Pin = OPT_INPUT_8_Pin|OPT_INPUT_10_Pin;
  GPIO_InitStruct.Mode = GPIO_MODE_INPUT;
  GPIO_InitStruct.Pull = GPIO_NOPULL;
  HAL_GPIO_Init(GPIOF, &GPIO_InitStruct);

  /*Configure GPIO pins : MUX_A1_Pin RELAY_DRIVER_nOE_Pin RELAY_DRIVER_SER_Pin VENTIL_DRIVER_SRCLK_Pin
                           VENTIL_DRIVER_RCLK_Pin */
  GPIO_InitStruct.Pin = MUX_A1_Pin|RELAY_DRIVER_nOE_Pin|RELAY_DRIVER_SER_Pin|VENTIL_DRIVER_SRCLK_Pin
                          |VENTIL_DRIVER_RCLK_Pin;
  GPIO_InitStruct.Mode = GPIO_MODE_OUTPUT_PP;
  GPIO_InitStruct.Pull = GPIO_NOPULL;
  GPIO_InitStruct.Speed = GPIO_SPEED_FREQ_LOW;
  HAL_GPIO_Init(GPIOG, &GPIO_InitStruct);

  /*Configure GPIO pin : MUX_A0_Pin */
  GPIO_InitStruct.Pin = MUX_A0_Pin;
  GPIO_InitStruct.Mode = GPIO_MODE_OUTPUT_PP;
  GPIO_InitStruct.Pull = GPIO_NOPULL;
  GPIO_InitStruct.Speed = GPIO_SPEED_FREQ_MEDIUM;
  HAL_GPIO_Init(MUX_A0_GPIO_Port, &GPIO_InitStruct);

  /*Configure GPIO pins : MUXes_Dout_1_Pin MUXes_Dout_2_Pin MUXes_Dout_3_Pin MUXes_Dout_4_Pin */
  GPIO_InitStruct.Pin = MUXes_Dout_1_Pin|MUXes_Dout_2_Pin|MUXes_Dout_3_Pin|MUXes_Dout_4_Pin;
  GPIO_InitStruct.Mode = GPIO_MODE_INPUT;
  GPIO_InitStruct.Pull = GPIO_NOPULL;
  HAL_GPIO_Init(GPIOE, &GPIO_InitStruct);

  /*Configure GPIO pin : MUXes_nEN_Pin */
  GPIO_InitStruct.Pin = MUXes_nEN_Pin;
  GPIO_InitStruct.Mode = GPIO_MODE_OUTPUT_PP;
  GPIO_InitStruct.Pull = GPIO_NOPULL;
  GPIO_InitStruct.Speed = GPIO_SPEED_FREQ_MEDIUM;
  HAL_GPIO_Init(MUXes_nEN_GPIO_Port, &GPIO_InitStruct);

  /*Configure GPIO pins : VENTIL_DRIVER_nSRCLR_Pin LAN_nRST_Pin STATUS_LED_GREEN_Pin STATUS_LED_Pin
                           RELAY_DRIVER_SRCLK_Pin RELAY_DRIVER_nSRCLR_Pin FDCAN1_S_Pin */
  GPIO_InitStruct.Pin = VENTIL_DRIVER_nSRCLR_Pin|LAN_nRST_Pin|STATUS_LED_GREEN_Pin|STATUS_LED_Pin
                          |RELAY_DRIVER_SRCLK_Pin|RELAY_DRIVER_nSRCLR_Pin|FDCAN1_S_Pin;
  GPIO_InitStruct.Mode = GPIO_MODE_OUTPUT_PP;
  GPIO_InitStruct.Pull = GPIO_NOPULL;
  GPIO_InitStruct.Speed = GPIO_SPEED_FREQ_LOW;
  HAL_GPIO_Init(GPIOD, &GPIO_InitStruct);

  /*Configure GPIO pins : FDCAN_SHDN_Pin IO_PD7_Pin */
  GPIO_InitStruct.Pin = FDCAN_SHDN_Pin|IO_PD7_Pin;
  GPIO_InitStruct.Mode = GPIO_MODE_INPUT;
  GPIO_InitStruct.Pull = GPIO_NOPULL;
  HAL_GPIO_Init(GPIOD, &GPIO_InitStruct);

  /*Configure GPIO pins : IO_PG9_Pin IO_PG10_Pin IO_PG11_Pin IO_PG12_Pin
                           IO_PG13_Pin IO_PG14_Pin CTRL_15_Pin */
  GPIO_InitStruct.Pin = IO_PG9_Pin|IO_PG10_Pin|IO_PG11_Pin|IO_PG12_Pin
                          |IO_PG13_Pin|IO_PG14_Pin|CTRL_15_Pin;
  GPIO_InitStruct.Mode = GPIO_MODE_INPUT;
  GPIO_InitStruct.Pull = GPIO_NOPULL;
  HAL_GPIO_Init(GPIOG, &GPIO_InitStruct);

}

/* USER CODE BEGIN 4 */

void vApplicationStackOverflowHook(TaskHandle_t xTask, char *pcTaskName)
{
  (void)xTask;
  DebugTrap("FreeRTOS stack overflow", pcTaskName);
}

void vApplicationMallocFailedHook(void)
{
  DebugTrap("FreeRTOS malloc failed", pcTaskGetName(NULL));
}

/* USER CODE END 4 */

void StartDefaultTask(void const * argument)
{
  /* init code for USB_DEVICE */
  MX_USB_DEVICE_Init();

  /* init code for LWIP */
  MX_LWIP_Init();
  /* USER CODE BEGIN 5 */
  HAL_DAC_SetValue(&hdac, DAC_CHANNEL_1, DAC_ALIGN_12B_R, 0x0);
  HAL_Delay(1000);
  xSemaphoreGive(InitDoneSemaphoreHandle);

  //Try to do it using bit banging method

  for(;;)
  {
    osDelay(1);
  }
  /* USER CODE END 5 */
}

void blinkTaskEntry(void const * argument)
{
  /* USER CODE BEGIN blinkTaskEntry */
  if (xSemaphoreTake(InitDoneSemaphoreHandle, portMAX_DELAY) != pdTRUE)
  {
    Error_Handler();
  }

  //return it
  xSemaphoreGive(InitDoneSemaphoreHandle);

  /* Infinite loop */
  HAL_GPIO_WritePin(STATUS_LED_GREEN_GPIO_Port, STATUS_LED_Pin, GPIO_PIN_SET);
  for(;;)
  {
    HAL_GPIO_TogglePin(STATUS_LED_GREEN_GPIO_Port, STATUS_LED_GREEN_Pin);
    osDelay(500);
  }
  /* USER CODE END blinkTaskEntry */
}

void watchDogReset(void const * argument)
{
  /* USER CODE BEGIN watchDogReset */
  /* Infinite loop */
  for(;;)
  {
    HAL_IWDG_Refresh(&hiwdg);
    osDelay(50);
  }
  /* USER CODE END watchDogReset */
}

void TcpServerTaskStart(void const * argument)
{
  /* USER CODE BEGIN TcpServerTaskStart */
    if (xSemaphoreTake(InitDoneSemaphoreHandle, portMAX_DELAY) != pdTRUE)
    {
      Error_Handler();
    }

    //return it
    xSemaphoreGive(InitDoneSemaphoreHandle);

    tcp_thread(NULL);
  /* USER CODE END TcpServerTaskStart */
}

void UsbTaskStart(void const * argument)
{
  /* USER CODE BEGIN UsbTaskStart */
  if (xSemaphoreTake(InitDoneSemaphoreHandle, portMAX_DELAY) != pdTRUE)
  {
    Error_Handler();
  }

  //return it
  xSemaphoreGive(InitDoneSemaphoreHandle);
  /* Infinite loop */
  for(;;)
  {
    parse_usb_message();
    osDelay(1);
  }
  /* USER CODE END UsbTaskStart */
}

void RS232TaskStart(void const * argument)
{
  /* USER CODE BEGIN RS232TaskStart */
  if (xSemaphoreTake(InitDoneSemaphoreHandle, portMAX_DELAY) != pdTRUE)
  {
    Error_Handler();
  }

  //The UART4 is connectet to RS232-1 and UART5 to RS232-2
  //Both are using circular DMA for reception..

  uart4_handler_struct.message_was_received_flag = 0U;
  uart4_handler_struct.message_length = 0U;
  uart4_handler_struct.last_char_pointer = 0U;
  uart4_handler_struct.dma_write_position = 0U;
  uart4_handler_struct.dma_pending_bytes = 0U;
  uart4_handler_struct.line_buffer_length = 0U;

  uart5_handler_struct.message_was_received_flag = 0U;
  uart5_handler_struct.message_length = 0U;
  uart5_handler_struct.last_char_pointer = 0U;
  uart5_handler_struct.dma_write_position = 0U;
  uart5_handler_struct.dma_pending_bytes = 0U;
  uart5_handler_struct.line_buffer_length = 0U;

  //ENABLE DMA reception for both UARTs
  if (HAL_UARTEx_ReceiveToIdle_DMA(&huart4, uart4_handler_struct.DMA_RX_buffer, CMD_UART_BUFFER_LENGTH) != HAL_OK)
  {
    Error_Handler();
  }
  __HAL_DMA_DISABLE_IT(huart4.hdmarx, DMA_IT_HT);

  if (HAL_UARTEx_ReceiveToIdle_DMA(&huart5, uart5_handler_struct.DMA_RX_buffer, CMD_UART_BUFFER_LENGTH) != HAL_OK)
  {
    Error_Handler();
  }
  __HAL_DMA_DISABLE_IT(huart5.hdmarx, DMA_IT_HT);

  //return it
  xSemaphoreGive(InitDoneSemaphoreHandle);

  //Start UART reception using DMA

  /* Infinite loop */
  for(;;)
  {
    parse_uart_message(&uart4_handler_struct);
    parse_uart_message(&uart5_handler_struct);
    osDelay(1);
  }
  /* USER CODE END RS232TaskStart */
}

void CommParserTaskStart(void const * argument)
{
  /* USER CODE BEGIN CommParserTaskStart */
  /* Infinite loop */
  for(;;)
  {

    //Read message queue and handle only valid dequeued commands.
    commandTemplate current_command;

    if(xQueueReceive(commandQueueHandle, &current_command, 0) == pdPASS){
      runCommand(&current_command);

      //print back response based on command sender
      if (current_command.source == USB_HANDLER) {
        printf("%s", current_command.response);
      }

      else if (current_command.source == RS232_HANDLER) {
        //send response via RS232
      }

      else if (current_command.source == TCP_THREAD) {
        //send response via TCP
        size_t total_len = strlen(current_command.response);
        size_t bytes_written = 0;

        while (bytes_written < total_len)
        {
          size_t chunk_written = 0;
          err_t write_err = netconn_write_partly(current_command.TCP_client_netconn,
                                                  current_command.response + bytes_written,
                                                  total_len - bytes_written,
                                                  NETCONN_COPY,
                                                  &chunk_written);

          bytes_written += chunk_written;

          if (write_err == ERR_OK)
          {
            continue;
          }

          if (write_err == ERR_WOULDBLOCK && chunk_written == 0)
          {
            osDelay(1);
            continue;
        }

          break;
        }

      }
    }
    osDelay(1);
  }
  /* USER CODE END CommParserTaskStart */
}

void HAL_TIM_PeriodElapsedCallback(TIM_HandleTypeDef *htim)
{
  /* USER CODE BEGIN Callback 0 */
  if (htim->Instance == TIM11) {
    _us_tick++;
  }

  if (htim->Instance == TIM7) {
    TIM_7_tick_1_us++;
  }

  /* USER CODE END Callback 0 */
  if (htim->Instance == TIM14)
  {
    HAL_IncTick();
  }
}

void Error_Handler(void)
{
  __disable_irq();
  while (1)
  {
  }
}
